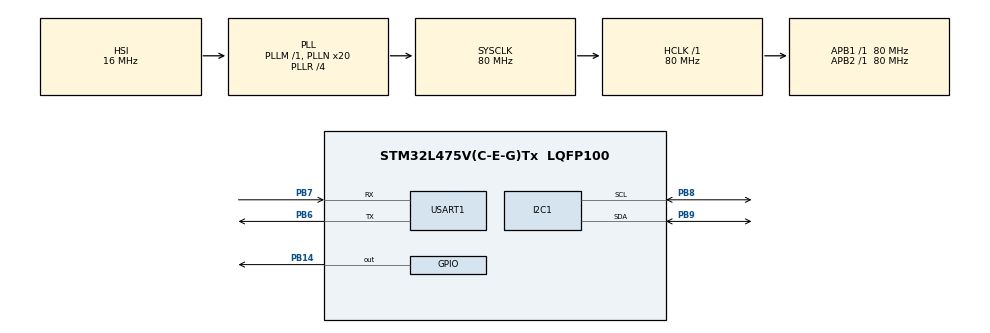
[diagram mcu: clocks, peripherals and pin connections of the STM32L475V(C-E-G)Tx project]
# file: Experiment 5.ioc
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I2C1.Timing=0x10D19CE4
Mcu.Family=STM32L4
Mcu.Name=STM32L475V(C-E-G)Tx
Mcu.Package=LQFP100
NVIC.PriorityGroup=NVIC_PRIORITYGROUP_4
PB14.Signal=GPIO_Output
PB6.Mode=Asynchronous
PB6.Signal=USART1_TX
PB7.Mode=Asynchronous
PB7.Signal=USART1_RX
PB8.Mode=I2C
PB8.Signal=I2C1_SCL
PB9.Mode=I2C
PB9.Signal=I2C1_SDA
PC14-OSC32_IN\ (PC14).Mode=LSE-External-Clock-Source
PC14-OSC32_IN\ (PC14).Signal=RCC_OSC32_IN
PH0-OSC_IN\ (PH0).Mode=HSE-External-Clock-Source
PH0-OSC_IN\ (PH0).Signal=RCC_OSC_IN
ProjectManager.HeapSize=0x200
ProjectManager.StackSize=0x400
ProjectManager.TargetToolchain=STM32CubeIDE
RCC.ADCFreq_Value=192000000
RCC.AHBFreq_Value=80000000
RCC.APB1Freq_Value=80000000
RCC.APB1TimFreq_Value=80000000
RCC.APB2Freq_Value=80000000
RCC.APB2TimFreq_Value=80000000
RCC.CortexFreq_Value=80000000
RCC.HCLKFreq_Value=80000000
RCC.HSE_VALUE=8000000
RCC.HSI_VALUE=16000000
RCC.LSE_VALUE=32768
RCC.MSI_VALUE=4000000
RCC.PLLN=20
RCC.PLLR=RCC_PLLR_DIV4
RCC.PLLSAI1N=24
RCC.PLLSourceVirtual=RCC_PLLSOURCE_HSI
RCC.SYSCLKFreq_VALUE=80000000
RCC.SYSCLKSource=RCC_SYSCLKSOURCE_PLLCLK
RCC.USBFreq_Value=192000000
RCC.VCOOutputFreq_Value=320000000
USART1.VirtualMode-Asynchronous=VM_ASYNC
board=B-L475E-IOT01A1

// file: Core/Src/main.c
/* USER CODE BEGIN Header */
/**
  ******************************************************************************
  * @file           : main.c
  * @brief          : Main program body
  ******************************************************************************
  * @attention
  *
  * Copyright (c) 2026 STMicroelectronics.
  * All rights reserved.
  *
  * This software is licensed under terms that can be found in the LICENSE file
  * in the root directory of this software component.
  * If no LICENSE file comes with this software, it is provided AS-IS.
  *
  ******************************************************************************
  */
/* USER CODE END Header */
#include "stm32l475e_iot01.h"
#include "lps22hb_driver.h"
#include "uart_console.h"
#include "stdlib.h"
#include <math.h>
#include <string.h>
#include <stdio.h>

I2C_HandleTypeDef hi2c1;

UART_HandleTypeDef huart1;

void SystemClock_Config(void);
static void MX_GPIO_Init(void);
static void MX_I2C1_Init(void);
static void MX_USART1_UART_Init(void);

int main(void)
{

  /* MCU Configuration--------------------------------------------------------*/

  /* Reset of all peripherals, Initializes the Flash interface and the Systick. */
  HAL_Init();

  /* Configure the system clock */
  SystemClock_Config();

  /* Initialize all configured peripherals */
  MX_GPIO_Init();
  MX_I2C1_Init();
  MX_USART1_UART_Init();
  /* USER CODE BEGIN 2 */
  lps22hb_data_t pressure;

  UART_Console_Init(&huart1);

  if (!LPS22HB_Init())
  {
      UART_Console_Print("LPS22HB init failed\r\n");
      while (1);
  }

  UART_Console_Print("LPS22HB initialized\r\n");

  /* USER CODE END 2 */

  /* Infinite loop */
  /* USER CODE BEGIN WHILE */
  while (1)
  {

	  if (LPS22HB_Read(&pressure))
	      {
	          UART_Console_Print("Pressure: %.1f hPa\r\n",
	                             pressure.pressure_hpa);
	      }

	      HAL_Delay(1000);

    /* USER CODE END WHILE */

  }
}

void SystemClock_Config(void)
{
  RCC_OscInitTypeDef RCC_OscInitStruct = {0};
  RCC_ClkInitTypeDef RCC_ClkInitStruct = {0};

  /** Configure the main internal regulator output voltage
  */
  if (HAL_PWREx_ControlVoltageScaling(PWR_REGULATOR_VOLTAGE_SCALE1) != HAL_OK)
  {
    Error_Handler();
  }

  /** Initializes the RCC Oscillators according to the specified parameters
  * in the RCC_OscInitTypeDef structure.
  */
  RCC_OscInitStruct.OscillatorType = RCC_OSCILLATORTYPE_HSI;
  RCC_OscInitStruct.HSIState = RCC_HSI_ON;
  RCC_OscInitStruct.HSICalibrationValue = RCC_HSICALIBRATION_DEFAULT;
  RCC_OscInitStruct.PLL.PLLState = RCC_PLL_ON;
  RCC_OscInitStruct.PLL.PLLSource = RCC_PLLSOURCE_HSI;
  RCC_OscInitStruct.PLL.PLLM = 1;
  RCC_OscInitStruct.PLL.PLLN = 20;
  RCC_OscInitStruct.PLL.PLLP = RCC_PLLP_DIV7;
  RCC_OscInitStruct.PLL.PLLQ = RCC_PLLQ_DIV2;
  RCC_OscInitStruct.PLL.PLLR = RCC_PLLR_DIV4;
  if (HAL_RCC_OscConfig(&RCC_OscInitStruct) != HAL_OK)
  {
    Error_Handler();
  }

  /** Initializes the CPU, AHB and APB buses clocks
  */
  RCC_ClkInitStruct.ClockType = RCC_CLOCKTYPE_HCLK|RCC_CLOCKTYPE_SYSCLK
                              |RCC_CLOCKTYPE_PCLK1|RCC_CLOCKTYPE_PCLK2;
  RCC_ClkInitStruct.SYSCLKSource = RCC_SYSCLKSOURCE_PLLCLK;
  RCC_ClkInitStruct.AHBCLKDivider = RCC_SYSCLK_DIV1;
  RCC_ClkInitStruct.APB1CLKDivider = RCC_HCLK_DIV1;
  RCC_ClkInitStruct.APB2CLKDivider = RCC_HCLK_DIV1;

  if (HAL_RCC_ClockConfig(&RCC_ClkInitStruct, FLASH_LATENCY_4) != HAL_OK)
  {
    Error_Handler();
  }
}

static void MX_I2C1_Init(void)
{

  hi2c1.Instance = I2C1;
  hi2c1.Init.Timing = 0x10D19CE4;
  hi2c1.Init.OwnAddress1 = 0;
  hi2c1.Init.AddressingMode = I2C_ADDRESSINGMODE_7BIT;
  hi2c1.Init.DualAddressMode = I2C_DUALADDRESS_DISABLE;
  hi2c1.Init.OwnAddress2 = 0;
  hi2c1.Init.OwnAddress2Masks = I2C_OA2_NOMASK;
  hi2c1.Init.GeneralCallMode = I2C_GENERALCALL_DISABLE;
  hi2c1.Init.NoStretchMode = I2C_NOSTRETCH_DISABLE;
  if (HAL_I2C_Init(&hi2c1) != HAL_OK)
  {
    Error_Handler();
  }

  /** Configure Analogue filter
  */
  if (HAL_I2CEx_ConfigAnalogFilter(&hi2c1, I2C_ANALOGFILTER_ENABLE) != HAL_OK)
  {
    Error_Handler();
  }

  /** Configure Digital filter
  */
  if (HAL_I2CEx_ConfigDigitalFilter(&hi2c1, 0) != HAL_OK)
  {
    Error_Handler();
  }

}

static void MX_USART1_UART_Init(void)
{

  huart1.Instance = USART1;
  huart1.Init.BaudRate = 115200;
  huart1.Init.WordLength = UART_WORDLENGTH_8B;
  huart1.Init.StopBits = UART_STOPBITS_1;
  huart1.Init.Parity = UART_PARITY_NONE;
  huart1.Init.Mode = UART_MODE_TX_RX;
  huart1.Init.HwFlowCtl = UART_HWCONTROL_NONE;
  huart1.Init.OverSampling = UART_OVERSAMPLING_16;
  huart1.Init.OneBitSampling = UART_ONE_BIT_SAMPLE_DISABLE;
  huart1.AdvancedInit.AdvFeatureInit = UART_ADVFEATURE_NO_INIT;
  if (HAL_UART_Init(&huart1) != HAL_OK)
  {
    Error_Handler();
  }

}

static void MX_GPIO_Init(void)
{
  GPIO_InitTypeDef GPIO_InitStruct = {0};

  /* GPIO Ports Clock Enable */
  __HAL_RCC_GPIOC_CLK_ENABLE();
  __HAL_RCC_GPIOH_CLK_ENABLE();
  __HAL_RCC_GPIOB_CLK_ENABLE();

  /*Configure GPIO pin Output Level */
  HAL_GPIO_WritePin(GPIOB, GPIO_PIN_14, GPIO_PIN_RESET);

  /*Configure GPIO pin : PB14 */
  GPIO_InitStruct.Pin = GPIO_PIN_14;
  GPIO_InitStruct.Mode = GPIO_MODE_OUTPUT_PP;
  GPIO_InitStruct.Pull = GPIO_NOPULL;
  GPIO_InitStruct.Speed = GPIO_SPEED_FREQ_LOW;
  HAL_GPIO_Init(GPIOB, &GPIO_InitStruct);

}

void Error_Handler(void)
{
  __disable_irq();
  while (1)
  {
  }
}
